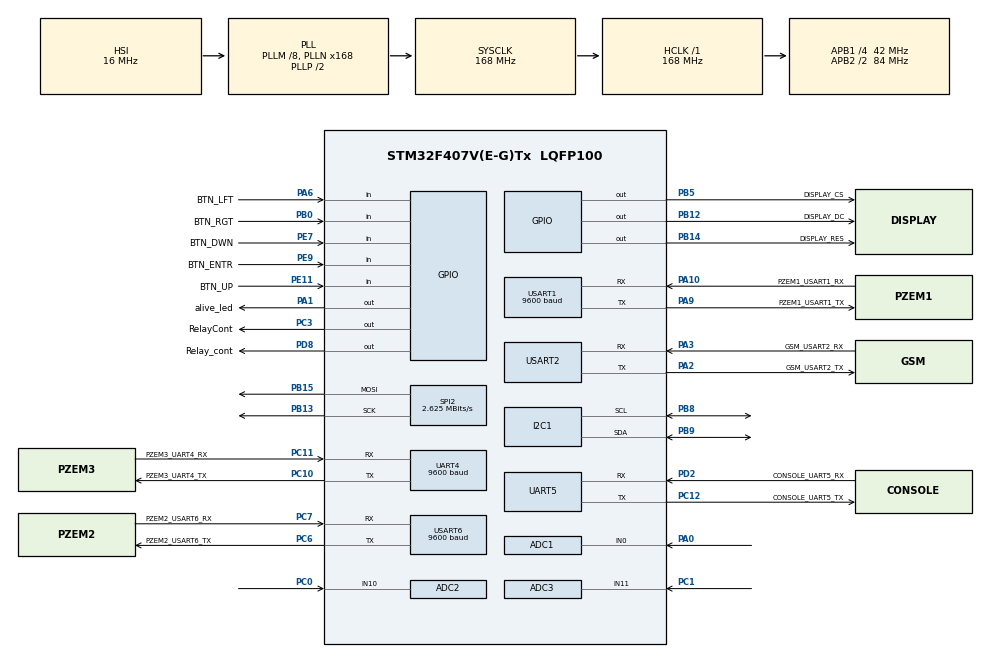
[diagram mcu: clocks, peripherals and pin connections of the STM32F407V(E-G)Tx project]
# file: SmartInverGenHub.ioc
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ADC1.Channel-0\#ChannelRegularConversion=ADC_CHANNEL_0
ADC1.NbrOfConversionFlag=1
ADC1.Rank-0\#ChannelRegularConversion=1
ADC1.SamplingTime-0\#ChannelRegularConversion=ADC_SAMPLETIME_480CYCLES
ADC1.master=1
ADC2.Channel-1\#ChannelRegularConversion=ADC_CHANNEL_10
ADC2.NbrOfConversionFlag=1
ADC2.Rank-1\#ChannelRegularConversion=1
ADC2.SamplingTime-1\#ChannelRegularConversion=ADC_SAMPLETIME_480CYCLES
ADC3.Channel-0\#ChannelRegularConversion=ADC_CHANNEL_11
ADC3.NbrOfConversionFlag=1
ADC3.Rank-0\#ChannelRegularConversion=1
ADC3.SamplingTime-0\#ChannelRegularConversion=ADC_SAMPLETIME_480CYCLES
FREERTOS.INCLUDE_xEventGroupSetBitFromISR=1
FREERTOS.Tasks01=defaultTask,24,128,StartDefaultTask,Default,NULL,Dynamic,NULL,NULL
FREERTOS.configENABLE_FPU=1
FREERTOS.configTIMER_TASK_PRIORITY=55
FREERTOS.configTOTAL_HEAP_SIZE=20000
FREERTOS.configUSE_NEWLIB_REENTRANT=1
FREERTOS.configUSE_OS2_EVENTFLAGS_FROM_ISR=0
FREERTOS.configUSE_OS2_MUTEX=0
FREERTOS.configUSE_OS2_THREAD_ENUMERATE=0
FREERTOS.configUSE_OS2_THREAD_FLAGS=0
FREERTOS.configUSE_OS2_THREAD_SUSPEND_RESUME=0
FREERTOS.configUSE_OS2_TIMER=0
IWDG.Prescaler=IWDG_PRESCALER_256
IWDG.Reload=2500
Mcu.Family=STM32F4
Mcu.Name=STM32F407V(E-G)Tx
Mcu.Package=LQFP100
Mcu.UserConstants=PZEM2_U,$$_USART6_IP_HANDLE_$$;PZEM3_U,$$_UART4_IP_HANDLE_$$;PZEM1_U,$$_USART1_IP_HANDLE_$$;GSM_U,$$_USART2_IP_HANDLE_$$;OLEDSpi,$$_SPI2_IP_HANDLE_$$;CONSOLE,$$_UART5_IP_HANDLE_$$
NVIC.PriorityGroup=NVIC_PRIORITYGROUP_4
NVIC.TIM3_IRQn=true\:15\:0\:false\:false\:true\:false\:false\:true\:true
NVIC.TimeBase=TIM3_IRQn
NVIC.TimeBaseIP=TIM3
NVIC.UART5_IRQn=true\:5\:0\:false\:false\:true\:true\:true\:true\:true
NVIC.USART2_IRQn=true\:5\:0\:false\:false\:true\:true\:true\:true\:true
PA0-WKUP.Signal=ADCx_IN0
PA1.GPIO_Label=alive_led
PA1.Signal=GPIO_Output
PA10.GPIO_Label=PZEM1_USART1_RX
PA10.Mode=Asynchronous
PA10.Signal=USART1_RX
PA13.Mode=Trace_Asynchronous_SW
PA13.Signal=SYS_JTMS-SWDIO
PA14.Mode=Trace_Asynchronous_SW
PA14.Signal=SYS_JTCK-SWCLK
PA2.GPIO_Label=GSM_USART2_TX
PA2.Mode=Asynchronous
PA2.Signal=USART2_TX
PA3.GPIO_Label=GSM_USART2_RX
PA3.Mode=Asynchronous
PA3.Signal=USART2_RX
PA6.GPIO_Label=BTN_LFT
PA6.GPIO_PuPd=GPIO_PULLUP
PA6.Signal=GPIO_Input
PA9.GPIO_Label=PZEM1_USART1_TX
PA9.Mode=Asynchronous
PA9.Signal=USART1_TX
PB0.GPIO_Label=BTN_RGT
PB0.GPIO_PuPd=GPIO_PULLUP
PB0.Signal=GPIO_Input
PB12.GPIO_Label=DISPLAY_DC
PB12.Signal=GPIO_Output
PB13.Mode=TX_Only_Simplex_Unidirect_Master
PB13.Signal=SPI2_SCK
PB14.GPIO_Label=DISPLAY_RES
PB14.Signal=GPIO_Output
PB15.Mode=TX_Only_Simplex_Unidirect_Master
PB15.Signal=SPI2_MOSI
PB3.Mode=Trace_Asynchronous_SW
PB3.Signal=SYS_JTDO-SWO
PB5.GPIO_Label=DISPLAY_CS
PB5.GPIO_Speed=GPIO_SPEED_FREQ_LOW
PB5.Signal=GPIO_Output
PB8.Mode=I2C
PB8.Signal=I2C1_SCL
PB9.Mode=I2C
PB9.Signal=I2C1_SDA
PC0.Signal=ADCx_IN10
PC1.Signal=ADCx_IN11
PC10.GPIO_Label=PZEM3_UART4_TX
PC10.Mode=Asynchronous
PC10.Signal=UART4_TX
PC11.GPIO_Label=PZEM3_UART4_RX
PC11.Mode=Asynchronous
PC11.Signal=UART4_RX
PC12.GPIO_Label=CONSOLE_UART5_TX
PC12.Mode=Asynchronous
PC12.Signal=UART5_TX
PC14-OSC32_IN.Mode=LSE-External-Oscillator
PC14-OSC32_IN.Signal=RCC_OSC32_IN
PC15-OSC32_OUT.Mode=LSE-External-Oscillator
PC15-OSC32_OUT.Signal=RCC_OSC32_OUT
PC3.GPIO_Label=RelayCont
PC3.Signal=GPIO_Output
PC6.GPIO_Label=PZEM2_USART6_TX
PC6.Mode=Asynchronous
PC6.Signal=USART6_TX
PC7.GPIO_Label=PZEM2_USART6_RX
PC7.Mode=Asynchronous
PC7.Signal=USART6_RX
PD2.GPIO_Label=CONSOLE_UART5_RX
PD2.Mode=Asynchronous
PD2.Signal=UART5_RX
PD8.GPIO_Label=Relay_cont
PD8.Signal=GPIO_Output
PE11.GPIO_Label=BTN_UP
PE11.GPIO_PuPd=GPIO_PULLUP
PE11.Signal=GPIO_Input
PE7.GPIO_Label=BTN_DWN
PE7.GPIO_PuPd=GPIO_PULLUP
PE7.Signal=GPIO_Input
PE9.GPIO_Label=BTN_ENTR
PE9.GPIO_PuPd=GPIO_PULLUP
PE9.Signal=GPIO_Input
PH0-OSC_IN.Mode=HSE-External-Oscillator
PH0-OSC_IN.Signal=RCC_OSC_IN
PH1-OSC_OUT.Mode=HSE-External-Oscillator
PH1-OSC_OUT.Signal=RCC_OSC_OUT
ProjectManager.HeapSize=0x200
ProjectManager.StackSize=0x400
ProjectManager.TargetToolchain=STM32CubeIDE
RCC.48MHZClocksFreq_Value=84000000
RCC.AHBFreq_Value=168000000
RCC.APB1CLKDivider=RCC_HCLK_DIV4
RCC.APB1Freq_Value=42000000
RCC.APB1TimFreq_Value=84000000
RCC.APB2CLKDivider=RCC_HCLK_DIV2
RCC.APB2Freq_Value=84000000
RCC.APB2TimFreq_Value=168000000
RCC.CortexFreq_Value=168000000
RCC.HCLKFreq_Value=168000000
RCC.HSE_VALUE=25000000
RCC.HSI_VALUE=16000000
RCC.PLLM=8
RCC.PLLN=168
RCC.RCC_RTC_Clock_Source=RCC_RTCCLKSOURCE_LSE
RCC.RCC_RTC_Clock_SourceVirtual=RCC_RTCCLKSOURCE_LSE
RCC.SYSCLKFreq_VALUE=168000000
RCC.SYSCLKSource=RCC_SYSCLKSOURCE_PLLCLK
RCC.VCOOutputFreq_Value=336000000
RTC.Format=RTC_FORMAT_BIN
SH.ADCx_IN0.0=ADC1_IN0,IN0
SH.ADCx_IN10.0=ADC2_IN10,IN10
SH.ADCx_IN11.0=ADC3_IN11,IN11
SPI2.BaudRatePrescaler=SPI_BAUDRATEPRESCALER_16
SPI2.CLKPhase=SPI_PHASE_2EDGE
SPI2.CLKPolarity=SPI_POLARITY_HIGH
SPI2.CalculateBaudRate=2.625 MBits/s
SPI2.Direction=SPI_DIRECTION_2LINES
SPI2.Mode=SPI_MODE_MASTER
SPI2.VirtualType=VM_MASTER
TIM8.AutoReloadPreload=TIM_AUTORELOAD_PRELOAD_DISABLE
TIM8.Period=2000-1
TIM8.Prescaler=168-1
TIM8.TIM_MasterOutputTrigger=TIM_TRGO_UPDATE
UART4.BaudRate=9600
UART4.VirtualMode=Asynchronous
UART5.VirtualMode=Asynchronous
USART1.BaudRate=9600
USART1.VirtualMode=VM_ASYNC
USART2.VirtualMode=VM_ASYNC
USART6.BaudRate=9600
USART6.VirtualMode=VM_ASYNC
VP_FREERTOS_VS_CMSIS_V2.Mode=CMSIS_V2
VP_IWDG_VS_IWDG.Mode=IWDG_Activate
VP_RTC_VS_RTC_Activate.Mode=RTC_Enabled
VP_RTC_VS_RTC_Calendar.Mode=RTC_Calendar
VP_SYS_VS_tim3.Mode=TIM3
VP_TIM8_VS_ClockSourceINT.Mode=Internal
board=custom

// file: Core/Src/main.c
/* USER CODE BEGIN Header */
/**
  ******************************************************************************
  * @file           : main.c
  * @brief          : Main program body
  ******************************************************************************
  * @attention
  *
  * Copyright (c) 2024 STMicroelectronics.
  * All rights reserved.
  *
  * This software is licensed under terms that can be found in the LICENSE file
  * in the root directory of this software component.
  * If no LICENSE file comes with this software, it is provided AS-IS.
  *
  ******************************************************************************
  */
/* USER CODE END Header */
#include "main.h"
#include "cmsis_os.h"
#include "adc.h"
#include "i2c.h"
#include "iwdg.h"
#include "rtc.h"
#include "spi.h"
#include "tim.h"
#include "usart.h"
#include "gpio.h"

void SystemClock_Config(void);
void MX_FREERTOS_Init(void);

int main(void)
{

  /* MCU Configuration--------------------------------------------------------*/

  /* Reset of all peripherals, Initializes the Flash interface and the Systick. */
  HAL_Init();

  /* Configure the system clock */
  SystemClock_Config();

  /* Initialize all configured peripherals */
  MX_GPIO_Init();
  MX_ADC1_Init();
  MX_I2C1_Init();
  MX_RTC_Init();
  MX_UART4_Init();
  MX_USART1_UART_Init();
  MX_USART2_UART_Init();
  MX_USART6_UART_Init();
  MX_TIM8_Init();
  MX_SPI2_Init();
  MX_ADC2_Init();
  MX_ADC3_Init();
  MX_IWDG_Init();
  MX_UART5_Init();
  /* USER CODE BEGIN 2 */
#ifdef disable_auto
  /* USER CODE END 2 */

  /* Init scheduler */
  osKernelInitialize();

  /* Call init function for freertos objects (in cmsis_os2.c) */
  MX_FREERTOS_Init();

  /* Start scheduler */
  osKernelStart();

  /* We should never get here as control is now taken by the scheduler */

  /* Infinite loop */
  /* USER CODE BEGIN WHILE */
#endif
  MX_FREERTOS_Init();
  while (1)
  {
    /* USER CODE END WHILE */

  }
}

void SystemClock_Config(void)
{
  RCC_OscInitTypeDef RCC_OscInitStruct = {0};
  RCC_ClkInitTypeDef RCC_ClkInitStruct = {0};

  /** Configure the main internal regulator output voltage
  */
  __HAL_RCC_PWR_CLK_ENABLE();
  __HAL_PWR_VOLTAGESCALING_CONFIG(PWR_REGULATOR_VOLTAGE_SCALE1);

  /** Initializes the RCC Oscillators according to the specified parameters
  * in the RCC_OscInitTypeDef structure.
  */
  RCC_OscInitStruct.OscillatorType = RCC_OSCILLATORTYPE_HSI|RCC_OSCILLATORTYPE_LSI
                              |RCC_OSCILLATORTYPE_LSE;
  RCC_OscInitStruct.LSEState = RCC_LSE_ON;
  RCC_OscInitStruct.HSIState = RCC_HSI_ON;
  RCC_OscInitStruct.HSICalibrationValue = RCC_HSICALIBRATION_DEFAULT;
  RCC_OscInitStruct.LSIState = RCC_LSI_ON;
  RCC_OscInitStruct.PLL.PLLState = RCC_PLL_ON;
  RCC_OscInitStruct.PLL.PLLSource = RCC_PLLSOURCE_HSI;
  RCC_OscInitStruct.PLL.PLLM = 8;
  RCC_OscInitStruct.PLL.PLLN = 168;
  RCC_OscInitStruct.PLL.PLLP = RCC_PLLP_DIV2;
  RCC_OscInitStruct.PLL.PLLQ = 4;
  if (HAL_RCC_OscConfig(&RCC_OscInitStruct) != HAL_OK)
  {
    Error_Handler();
  }

  /** Initializes the CPU, AHB and APB buses clocks
  */
  RCC_ClkInitStruct.ClockType = RCC_CLOCKTYPE_HCLK|RCC_CLOCKTYPE_SYSCLK
                              |RCC_CLOCKTYPE_PCLK1|RCC_CLOCKTYPE_PCLK2;
  RCC_ClkInitStruct.SYSCLKSource = RCC_SYSCLKSOURCE_PLLCLK;
  RCC_ClkInitStruct.AHBCLKDivider = RCC_SYSCLK_DIV1;
  RCC_ClkInitStruct.APB1CLKDivider = RCC_HCLK_DIV4;
  RCC_ClkInitStruct.APB2CLKDivider = RCC_HCLK_DIV2;

  if (HAL_RCC_ClockConfig(&RCC_ClkInitStruct, FLASH_LATENCY_5) != HAL_OK)
  {
    Error_Handler();
  }
}

void HAL_TIM_PeriodElapsedCallback(TIM_HandleTypeDef *htim)
{
  if (htim->Instance == TIM3)
  {
    HAL_IncTick();
  }
}

void Error_Handler(void)
{
  __disable_irq();
  while (1)
  {
  }
}

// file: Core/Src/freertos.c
/* USER CODE BEGIN Header */
#ifdef disable_auto
/**
  ******************************************************************************
  * File Name          : freertos.c
  * Description        : Code for freertos applications
  ******************************************************************************
  * @attention
  *
  * Copyright (c) 2024 STMicroelectronics.
  * All rights reserved.
  *
  * This software is licensed under terms that can be found in the LICENSE file
  * in the root directory of this software component.
  * If no LICENSE file comes with this software, it is provided AS-IS.
  *
  ******************************************************************************
  */
/* USER CODE END Header */

#include "FreeRTOS.h"
#include "task.h"
#include "main.h"
#include "cmsis_os.h"

/* Definitions for defaultTask */
osThreadId_t defaultTaskHandle;
const osThreadAttr_t defaultTask_attributes = {
  .name = "defaultTask",
  .stack_size = 128 * 4,
  .priority = (osPriority_t) osPriorityNormal,
};

void StartDefaultTask(void *argument);

void MX_FREERTOS_Init(void); /* (MISRA C 2004 rule 8.1) */

void MX_FREERTOS_Init(void) {

  /* Create the thread(s) */
  /* creation of defaultTask */
  defaultTaskHandle = osThreadNew(StartDefaultTask, NULL, &defaultTask_attributes);

}

void StartDefaultTask(void *argument)
{
  for(;;)
  {
    osDelay(1);
  }
}

/* USER CODE BEGIN Application */
#endif
#include "FreeRTOS.h"
#include "task.h"
#include "main.h"
#include "app_main.hpp"

void MX_FREERTOS_Init(void); /* (MISRA C 2004 rule 8.1) */

void MX_FREERTOS_Init(void) {

	app_mainC();
    vTaskStartScheduler();
}

/* USER CODE END Application */
